# DSI1_A_L3_MAIN register map
Vendor: Texas Instruments
Peripheral module from a debugger description file (folder am571x).
Registers are 32-bit, access per field, reset 0x1 unless marked. A register's access mark holds for its fields unless they carry their own. Offsets are as the file gives them; lines under a group give offsets from that group; [hi:lo] are bit positions; {n}, {i} and the like mark numbered series; 'fields as' and 'values as' point back to an identical list; <NAME> marks a mode.

## DSI1_A_L3_MAIN
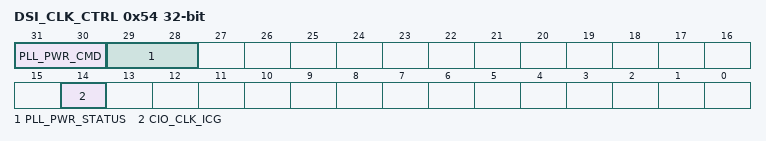
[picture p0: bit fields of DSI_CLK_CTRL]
0x54 DSI_CLK_CTRL — CLOCK CONTROL This register controls the CLOCK GENERATION. The register can be modified only when IF_EN is reset.
  [31:30] PLL_PWR_CMD rw — Command for power control of the DSI PLL Control Module 0x0: Command to change to OFF state 0x1: Command to change to ON state for PLL only (HSDIVISER is OFF) 0x2: Command to change to ON state for both PLL and HSDIVISER 0x3: Command to change to ON state for both PLL and HSDIVISER (no clock output to the DSI PHY)
  [29:28] PLL_PWR_STATUS ro — Status of the power control of the DSI PLL Control module Read 0x0: DSI PLL Control module in OFF state Read 0x1: DSI PLL Control module in ON state for PLL only (HSDIVISER is OFF) Read 0x2: DSI PLL Control module in ON state for both PLL and HSDIVISER Read 0x3: DSI PLL Control module in ON state for both PLL and HSDIVISER (no clock output to the DSI PHY)
  [14] CIO_CLK_ICG rw — Gates SCPClk clock provided to DSI-PHY and PLL-CTRL module. 0x0: Disabled. SCPClk is not generated. It remains at 0. 0x1: Enabled. SCPClk is generated (OCP_CLK/4)
